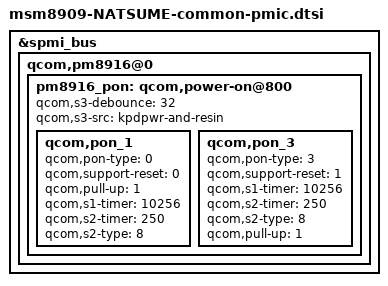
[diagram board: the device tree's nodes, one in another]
/*
 * This software is contributed or developed by KYOCERA Corporation.
 * (C) 2019 KYOCERA Corporation
 *
 * This program is free software; you can redistribute it and/or modify
 * it under the terms of the GNU General Public License version 2 and
 * only version 2 as published by the Free Software Foundation.
 *
 * This program is distributed in the hope that it will be useful,
 * but WITHOUT ANY WARRANTY; without even the implied warranty of
 * MERCHANTABILITY or FITNESS FOR A PARTICULAR PURPOSE.  See the
 * GNU General Public License for more details.
 */

&spmi_bus {

	qcom,pm8916@0 {

		pm8916_pon: qcom,power-on@800 {
			qcom,s3-debounce = <32>;
			qcom,s3-src = "kpdpwr-and-resin";

			qcom,pon_1 {
				qcom,pon-type = <0>;
				qcom,support-reset = <0>;
				qcom,pull-up = <1>;
				qcom,s1-timer = <10256>;
				qcom,s2-timer = <250>;
				qcom,s2-type = <8>;
			};

			qcom,pon_3 {
				qcom,pon-type = <3>;
				qcom,support-reset = <1>;
				qcom,s1-timer = <10256>;
				qcom,s2-timer = <250>;
				qcom,s2-type = <8>;
				qcom,pull-up = <1>;
			};
		};
	};
};
